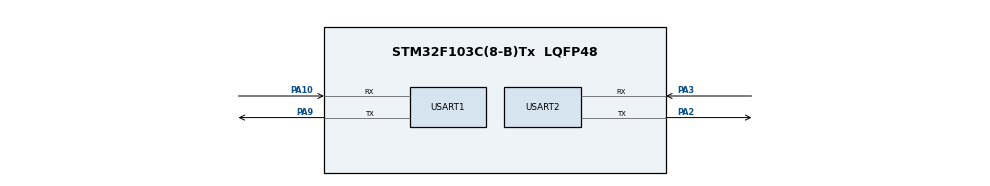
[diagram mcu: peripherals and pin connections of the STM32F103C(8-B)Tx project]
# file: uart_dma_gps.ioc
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Dma.Request0=USART1_RX
Dma.USART1_RX.0.Direction=DMA_PERIPH_TO_MEMORY
Dma.USART1_RX.0.Instance=DMA1_Channel5
Dma.USART1_RX.0.MemDataAlignment=DMA_MDATAALIGN_BYTE
Dma.USART1_RX.0.MemInc=DMA_MINC_ENABLE
Dma.USART1_RX.0.Mode=DMA_CIRCULAR
Dma.USART1_RX.0.PeriphDataAlignment=DMA_PDATAALIGN_BYTE
Dma.USART1_RX.0.PeriphInc=DMA_PINC_DISABLE
Dma.USART1_RX.0.Priority=DMA_PRIORITY_LOW
Mcu.Family=STM32F1
Mcu.Name=STM32F103C(8-B)Tx
Mcu.Package=LQFP48
NVIC.DMA1_Channel5_IRQn=true\:0\:0\:false\:false\:true\:false\:true
NVIC.PriorityGroup=NVIC_PRIORITYGROUP_4
PA10.Mode=Asynchronous
PA10.Signal=USART1_RX
PA13.Mode=Serial_Wire
PA13.Signal=SYS_JTMS-SWDIO
PA14.Mode=Serial_Wire
PA14.Signal=SYS_JTCK-SWCLK
PA2.Mode=Asynchronous
PA2.Signal=USART2_TX
PA3.Mode=Asynchronous
PA3.Signal=USART2_RX
PA9.Mode=Asynchronous
PA9.Signal=USART1_TX
PD0-OSC_IN.Mode=HSE-External-Oscillator
PD0-OSC_IN.Signal=RCC_OSC_IN
PD1-OSC_OUT.Mode=HSE-External-Oscillator
PD1-OSC_OUT.Signal=RCC_OSC_OUT
ProjectManager.HeapSize=0x200
ProjectManager.StackSize=0x400
ProjectManager.TargetToolchain=STM32CubeIDE
RCC.APB1Freq_Value=8000000
RCC.APB2Freq_Value=8000000
USART1.VirtualMode=VM_ASYNC
USART2.VirtualMode=VM_ASYNC
board=custom

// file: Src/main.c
/* USER CODE BEGIN Header */
/**
  ******************************************************************************
  * @file           : main.c
  * @brief          : Main program body
  ******************************************************************************
  * @attention
  *
  * <h2><center>&copy; Copyright (c) 2019 STMicroelectronics.
  * All rights reserved.</center></h2>
  *
  * This software component is licensed by ST under BSD 3-Clause license,
  * the "License"; You may not use this file except in compliance with the
  * License. You may obtain a copy of the License at:
  *                        opensource.org/licenses/BSD-3-Clause
  *
  ******************************************************************************
  */
/* USER CODE END Header */

#include "main.h"

UART_HandleTypeDef huart1;
UART_HandleTypeDef huart2;
DMA_HandleTypeDef hdma_usart1_rx;

void SystemClock_Config(void);
static void MX_GPIO_Init(void);
static void MX_DMA_Init(void);
static void MX_USART1_UART_Init(void);
static void MX_USART2_UART_Init(void);

/* USER CODE BEGIN 0 */
char Rx_data[2];
char Rx_indx,Rx_indx1, Rx_data[2], Rx_Buffer[100],temp[50], Transfer_cplt;
/* USER CODE END 0 */

int main(void)
{

  /* MCU Configuration--------------------------------------------------------*/

  /* Reset of all peripherals, Initializes the Flash interface and the Systick. */
  HAL_Init();

  /* Configure the system clock */
  SystemClock_Config();

  /* Initialize all configured peripherals */
  MX_GPIO_Init();
  MX_DMA_Init();
  MX_USART1_UART_Init();
  MX_USART2_UART_Init();
  /* USER CODE BEGIN 2 */
  HAL_UART_Receive_DMA(&huart1, Rx_data, 1);
  /* USER CODE END 2 */

  /* Infinite loop */
  while (1)
  {

  }
}

void SystemClock_Config(void)
{
  RCC_OscInitTypeDef RCC_OscInitStruct = {0};
  RCC_ClkInitTypeDef RCC_ClkInitStruct = {0};

  /** Initializes the CPU, AHB and APB busses clocks
  */
  RCC_OscInitStruct.OscillatorType = RCC_OSCILLATORTYPE_HSI;
  RCC_OscInitStruct.HSIState = RCC_HSI_ON;
  RCC_OscInitStruct.HSICalibrationValue = RCC_HSICALIBRATION_DEFAULT;
  RCC_OscInitStruct.PLL.PLLState = RCC_PLL_NONE;
  if (HAL_RCC_OscConfig(&RCC_OscInitStruct) != HAL_OK)
  {
    Error_Handler();
  }
  /** Initializes the CPU, AHB and APB busses clocks
  */
  RCC_ClkInitStruct.ClockType = RCC_CLOCKTYPE_HCLK|RCC_CLOCKTYPE_SYSCLK
                              |RCC_CLOCKTYPE_PCLK1|RCC_CLOCKTYPE_PCLK2;
  RCC_ClkInitStruct.SYSCLKSource = RCC_SYSCLKSOURCE_HSI;
  RCC_ClkInitStruct.AHBCLKDivider = RCC_SYSCLK_DIV1;
  RCC_ClkInitStruct.APB1CLKDivider = RCC_HCLK_DIV1;
  RCC_ClkInitStruct.APB2CLKDivider = RCC_HCLK_DIV1;

  if (HAL_RCC_ClockConfig(&RCC_ClkInitStruct, FLASH_LATENCY_0) != HAL_OK)
  {
    Error_Handler();
  }
}

static void MX_USART1_UART_Init(void)
{

  huart1.Instance = USART1;
  huart1.Init.BaudRate = 115200;
  huart1.Init.WordLength = UART_WORDLENGTH_8B;
  huart1.Init.StopBits = UART_STOPBITS_1;
  huart1.Init.Parity = UART_PARITY_NONE;
  huart1.Init.Mode = UART_MODE_TX_RX;
  huart1.Init.HwFlowCtl = UART_HWCONTROL_NONE;
  huart1.Init.OverSampling = UART_OVERSAMPLING_16;
  if (HAL_UART_Init(&huart1) != HAL_OK)
  {
    Error_Handler();
  }

}

static void MX_USART2_UART_Init(void)
{

  huart2.Instance = USART2;
  huart2.Init.BaudRate = 115200;
  huart2.Init.WordLength = UART_WORDLENGTH_8B;
  huart2.Init.StopBits = UART_STOPBITS_1;
  huart2.Init.Parity = UART_PARITY_NONE;
  huart2.Init.Mode = UART_MODE_TX_RX;
  huart2.Init.HwFlowCtl = UART_HWCONTROL_NONE;
  huart2.Init.OverSampling = UART_OVERSAMPLING_16;
  if (HAL_UART_Init(&huart2) != HAL_OK)
  {
    Error_Handler();
  }

}

static void MX_DMA_Init(void)
{

  /* DMA controller clock enable */
  __HAL_RCC_DMA1_CLK_ENABLE();

  /* DMA interrupt init */
  /* DMA1_Channel5_IRQn interrupt configuration */
  HAL_NVIC_SetPriority(DMA1_Channel5_IRQn, 0, 0);
  HAL_NVIC_EnableIRQ(DMA1_Channel5_IRQn);

}

static void MX_GPIO_Init(void)
{

  /* GPIO Ports Clock Enable */
  __HAL_RCC_GPIOD_CLK_ENABLE();
  __HAL_RCC_GPIOA_CLK_ENABLE();

}

/* USER CODE BEGIN 4 */
void HAL_UART_RxCpltCallback(UART_HandleTypeDef *huart)
{
	uint8_t i;

	        if (Rx_data[0]!=10) //if received data different from ascii 13 (enter)
	            {
	            Rx_Buffer[Rx_indx++]=Rx_data[0];    //add data to Rx_Buffer
	            }
	        else            //if received data = 13
	            {
	        	//Rx_Buffer[Rx_indx++] = 13;
	            Rx_indx=0;
	            char * t = "\n";
	            Transfer_cplt=1;//transfer complete, data is ready to read

	            //HAL_UART_Transmit(&huart2, (uint8_t *) Rx_Buffer, sizeof(Rx_Buffer),1000);

	//
	//            			sscanf(Rx_Buffer,"$GNRMC,%2hhd%2hhd%2hhd.%3hd,%f,%c,%f,%c,%f,%f,%d,%f,%c,*%c\r\n",
	//            					gps.UTC_Hour,gps.UTC_Min,gps.UTC_Sec,gps.UTC_MicroSec,gps.Lat,gps.Lat_Dir,
	//								gps.Lon,gps.Lon_Dir,gps.Speed,gps.Track,gps.date,gps.mag_v,gps.var_dir,gps.mode_ind
	//								);
	            HAL_UART_Transmit(&huart2, (uint8_t *) t, sizeof(t),1000);

	            }

}
/* USER CODE END 4 */

void Error_Handler(void)
{
}

/************************ (C) COPYRIGHT STMicroelectronics *****END OF FILE****/
